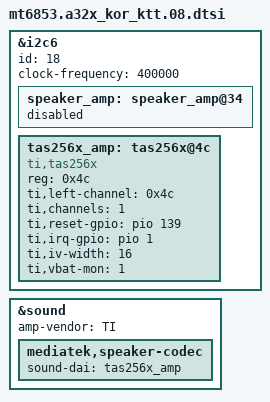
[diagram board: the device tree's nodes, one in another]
/*
 * Generated by Samsung
 * If these files should be changed, then please make a sync with MTK
*/

#include "../../mediatek/k6853v1_64_titan/gpio08_kor.dtsi"
#include "mt6853-a32x_common.dtsi"
#include "mt6853-a32x_camera_03.dtsi"
#include "mt6853-a32x_kor_gripsensor_00.dtsi"
#include "display_lcd_a32x_common.dtsi"
#include "mt6853_input_a32x_05.dtsi"

&i2c6 {
	speaker_amp: speaker_amp@34 {
		status = "disabled";
	};
};

&i2c6 {
	status = "okay";
	id = <18>;
	clock-frequency = <400000>;
	#address-cells = <1>;
	#size-cells = <0>;

	tas256x_amp: tas256x@4c {
		#sound-dai-cells = <0>;
		compatible = "ti,tas256x";
		reg = <0x4c>;
		ti,left-channel = <0x4c>;
		ti,channels = <1>;
		ti,reset-gpio = <&pio 139 0>;
		ti,irq-gpio = <&pio 1 0>;
		status = "okay";
		ti,iv-width = <16>;
		ti,vbat-mon = <1>;
	};
};

&sound {
	amp-vendor = "TI";
	mediatek,speaker-codec {
		sound-dai = <&tas256x_amp>;
	};
};
/*End of this file, DO NOT ADD ANYTHING HERE*/
